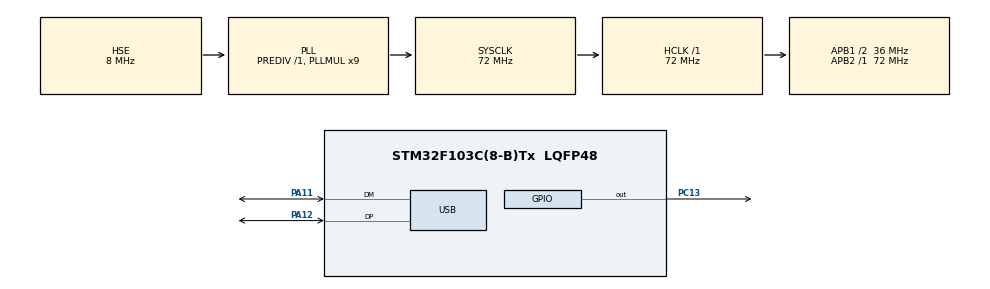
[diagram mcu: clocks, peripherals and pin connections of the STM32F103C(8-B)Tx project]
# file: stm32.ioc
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FREERTOS.Tasks01=defaultTask,24,128,StartDefaultTask,Default,NULL,Dynamic,NULL,NULL
FREERTOS.configTOTAL_HEAP_SIZE=1024*4
Mcu.Family=STM32F1
Mcu.Name=STM32F103C(8-B)Tx
Mcu.Package=LQFP48
NVIC.PriorityGroup=NVIC_PRIORITYGROUP_4
NVIC.TIM2_IRQn=true\:15\:0\:false\:false\:true\:false\:false\:true\:true
NVIC.TimeBase=TIM2_IRQn
NVIC.TimeBaseIP=TIM2
NVIC.USB_LP_CAN1_RX0_IRQn=true\:5\:0\:false\:false\:true\:true\:false\:true\:true
PA11.Mode=Device
PA11.Signal=USB_DM
PA12.Mode=Device
PA12.Signal=USB_DP
PA13.Mode=Serial_Wire
PA13.Signal=SYS_JTMS-SWDIO
PA14.Mode=Serial_Wire
PA14.Signal=SYS_JTCK-SWCLK
PC13-TAMPER-RTC.Signal=GPIO_Output
PD0-OSC_IN.Mode=HSE-External-Oscillator
PD0-OSC_IN.Signal=RCC_OSC_IN
PD1-OSC_OUT.Mode=HSE-External-Oscillator
PD1-OSC_OUT.Signal=RCC_OSC_OUT
ProjectManager.HeapSize=0x200
ProjectManager.StackSize=0x400
ProjectManager.TargetToolchain=CMake
RCC.AHBFreq_Value=72000000
RCC.APB1CLKDivider=RCC_HCLK_DIV2
RCC.APB1Freq_Value=36000000
RCC.APB1TimFreq_Value=72000000
RCC.APB2Freq_Value=72000000
RCC.APB2TimFreq_Value=72000000
RCC.HCLKFreq_Value=72000000
RCC.PLLMUL=RCC_PLL_MUL9
RCC.PLLSourceVirtual=RCC_PLLSOURCE_HSE
RCC.SYSCLKFreq_VALUE=72000000
RCC.SYSCLKSource=RCC_SYSCLKSOURCE_PLLCLK
RCC.USBFreq_Value=48000000
RCC.USBPrescaler=RCC_USBCLKSOURCE_PLL_DIV1_5
USB_DEVICE.CLASS_NAME_FS=CDC
USB_DEVICE.VirtualMode=Cdc
USB_DEVICE.VirtualModeFS=Cdc_FS
VP_FREERTOS_VS_CMSIS_V2.Mode=CMSIS_V2
VP_SYS_VS_tim2.Mode=TIM2
VP_USB_DEVICE_VS_USB_DEVICE_CDC_FS.Mode=CDC_FS
board=custom

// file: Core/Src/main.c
/* USER CODE BEGIN Header */
/**
 ******************************************************************************
 * @file           : main.c
 * @brief          : Main program body
 ******************************************************************************
 * @attention
 *
 * Copyright (c) 2025 STMicroelectronics.
 * All rights reserved.
 *
 * This software is licensed under terms that can be found in the LICENSE file
 * in the root directory of this software component.
 * If no LICENSE file comes with this software, it is provided AS-IS.
 *
 ******************************************************************************
 */
/* USER CODE END Header */
#include "main.h"
#include "cmsis_os.h"
#include "usb_device.h"

/* USER CODE BEGIN Includes */
#include "usbd_cdc_if.h"

#include "queue.h"
#include "stream_buffer.h"

#include "cs_usb_comms.h"
/* USER CODE END Includes */

/* USER CODE BEGIN PD */
#define CMD_BUFFER_MAX_LEN 32
#define CS_DEFAULT_PRIORITY (osPriorityNormal)

/* USER CODE END PD */

/* Definitions for defaultTask */
osThreadId_t defaultTaskHandle;
const osThreadAttr_t defaultTask_attributes = {
    .name = "defaultTask",
    .stack_size = 128 * 4,
    .priority = (osPriority_t)osPriorityNormal,
};
/* USER CODE BEGIN PV */
StreamBufferHandle_t sb_usb_recv_buffer;
QueueHandle_t q_usb_send_queue;

/* USER CODE END PV */

void SystemClock_Config(void);
static void MX_GPIO_Init(void);
void StartDefaultTask(void *argument);

/* USER CODE BEGIN PFP */
void usb_recv_ISR(uint8_t *buf, uint32_t len);

void task_usb_receiver(void *pargs);
void task_usb_sender(void *pargs);

/* USER CODE END PFP */

/* USER CODE BEGIN 0 */

void toggle_led()
{
    HAL_GPIO_TogglePin(GPIOC, GPIO_PIN_13);
}

/* USER CODE END 0 */

int main(void)
{

    /* MCU Configuration--------------------------------------------------------*/

    /* Reset of all peripherals, Initializes the Flash interface and the Systick. */
    HAL_Init();

    /* Configure the system clock */
    SystemClock_Config();

    /* Initialize all configured peripherals */
    MX_GPIO_Init();

    /* Init scheduler */
    osKernelInitialize();

    /* USER CODE BEGIN RTOS_QUEUES */
    q_usb_send_queue = xQueueCreate(2, sizeof(cs_response_msg));
    sb_usb_recv_buffer = xStreamBufferCreate(64, 1);
    /* USER CODE END RTOS_QUEUES */

    /* Create the thread(s) */
    /* creation of defaultTask */
    defaultTaskHandle = osThreadNew(StartDefaultTask, NULL, &defaultTask_attributes);

    /* USER CODE BEGIN RTOS_THREADS */
    BaseType_t created;
    created = xTaskCreate(task_usb_sender,
                          "senderTask",
                          configMINIMAL_STACK_SIZE,
                          NULL,
                          CS_DEFAULT_PRIORITY,
                          NULL);

    configASSERT(pdPASS == created);

    created = xTaskCreate(task_usb_receiver,
                          "recvTask",
                          configMINIMAL_STACK_SIZE * 3,
                          NULL,
                          CS_DEFAULT_PRIORITY,
                          NULL);

    configASSERT(pdPASS == created);
    /* USER CODE END RTOS_THREADS */

    /* Start scheduler */
    osKernelStart();

    /* We should never get here as control is now taken by the scheduler */

    /* Infinite loop */
    while (1)
    {

    }
}

void SystemClock_Config(void)
{
    RCC_OscInitTypeDef RCC_OscInitStruct = {0};
    RCC_ClkInitTypeDef RCC_ClkInitStruct = {0};
    RCC_PeriphCLKInitTypeDef PeriphClkInit = {0};

    /** Initializes the RCC Oscillators according to the specified parameters
     * in the RCC_OscInitTypeDef structure.
     */
    RCC_OscInitStruct.OscillatorType = RCC_OSCILLATORTYPE_HSE;
    RCC_OscInitStruct.HSEState = RCC_HSE_ON;
    RCC_OscInitStruct.HSEPredivValue = RCC_HSE_PREDIV_DIV1;
    RCC_OscInitStruct.HSIState = RCC_HSI_ON;
    RCC_OscInitStruct.PLL.PLLState = RCC_PLL_ON;
    RCC_OscInitStruct.PLL.PLLSource = RCC_PLLSOURCE_HSE;
    RCC_OscInitStruct.PLL.PLLMUL = RCC_PLL_MUL9;
    if (HAL_RCC_OscConfig(&RCC_OscInitStruct) != HAL_OK)
    {
        Error_Handler();
    }

    /** Initializes the CPU, AHB and APB buses clocks
     */
    RCC_ClkInitStruct.ClockType = RCC_CLOCKTYPE_HCLK | RCC_CLOCKTYPE_SYSCLK | RCC_CLOCKTYPE_PCLK1 | RCC_CLOCKTYPE_PCLK2;
    RCC_ClkInitStruct.SYSCLKSource = RCC_SYSCLKSOURCE_PLLCLK;
    RCC_ClkInitStruct.AHBCLKDivider = RCC_SYSCLK_DIV1;
    RCC_ClkInitStruct.APB1CLKDivider = RCC_HCLK_DIV2;
    RCC_ClkInitStruct.APB2CLKDivider = RCC_HCLK_DIV1;

    if (HAL_RCC_ClockConfig(&RCC_ClkInitStruct, FLASH_LATENCY_2) != HAL_OK)
    {
        Error_Handler();
    }
    PeriphClkInit.PeriphClockSelection = RCC_PERIPHCLK_USB;
    PeriphClkInit.UsbClockSelection = RCC_USBCLKSOURCE_PLL_DIV1_5;
    if (HAL_RCCEx_PeriphCLKConfig(&PeriphClkInit) != HAL_OK)
    {
        Error_Handler();
    }
}

static void MX_GPIO_Init(void)
{
    GPIO_InitTypeDef GPIO_InitStruct = {0};

    /* GPIO Ports Clock Enable */
    __HAL_RCC_GPIOC_CLK_ENABLE();
    __HAL_RCC_GPIOD_CLK_ENABLE();
    __HAL_RCC_GPIOA_CLK_ENABLE();

    /*Configure GPIO pin Output Level */
    HAL_GPIO_WritePin(GPIOC, GPIO_PIN_13, GPIO_PIN_RESET);

    /*Configure GPIO pin : PC13 */
    GPIO_InitStruct.Pin = GPIO_PIN_13;
    GPIO_InitStruct.Mode = GPIO_MODE_OUTPUT_PP;
    GPIO_InitStruct.Pull = GPIO_NOPULL;
    GPIO_InitStruct.Speed = GPIO_SPEED_FREQ_LOW;
    HAL_GPIO_Init(GPIOC, &GPIO_InitStruct);

}

/* USER CODE BEGIN 4 */
void usb_recv_ISR(uint8_t *buf, uint32_t len)
{
    BaseType_t xHigherPriorityTaskWoken = pdFALSE;

    xStreamBufferSendFromISR(sb_usb_recv_buffer, buf, len,
                             &xHigherPriorityTaskWoken);

    portYIELD_FROM_ISR(xHigherPriorityTaskWoken);
}

void task_usb_receiver(void *arg)
{
    for (;;)
    {
        size_t n = xStreamBufferReceive(sb_usb_recv_buffer,
                                        (void *)cs_get_remaining_cmd_buffer(),
                                        cs_get_remaining_cmd_buffer_len(),
                                        portMAX_DELAY);

        if (n == 0)
        {
            continue;
        }

        cs_updated_cmd_buffer(n);

        cs_command_id cmd;

        if (!cs_check_for_command(&cmd))
        {
            continue;
        }

        // cs_response_msg resp;

        switch (cmd)
        {
        case CMD_TOGGLE_LED:
            HAL_GPIO_TogglePin(GPIOC, GPIO_PIN_13);
            // resp.id = RESP_TEXT;
            // resp.payload = (cs_response_payload){
            //     .text = "OK"
            // };
            // cs_usb_send_blocking(&resp);
            break;
        case CMD_PING:
        {
            cs_response_msg resp = {.id = RESP_TEXT, .payload.text = "PONG"};
            xQueueSend(q_usb_send_queue, &resp, portMAX_DELAY);
            break;
        }
        case CMD_ERR:
        default:
        {
            cs_response_msg resp = {.id = RESP_ERR, .payload.text = "unknown cmd"};
            xQueueSend(q_usb_send_queue, &resp, portMAX_DELAY);
            break;
        }
        }
    }
}

void task_usb_sender(void *arg)
{
    for (;;)
    {
        cs_response_msg resp = {0};

        if (pdPASS != xQueueReceive(q_usb_send_queue, &resp, portMAX_DELAY))
        {
            continue;
        }

        switch (resp.id)
        {
        default:
            // use text buffer by default
            size_t len = strnlen(resp.payload.text, sizeof(resp.payload.text));
            CDC_Transmit_FS((uint8_t *)resp.payload.text, len);
            break;
        }
    }
}

// FreeRTOS hooks/assert hanndler
void vApplicationMallocFailedHook(void)
{
    taskDISABLE_INTERRUPTS();
    for (;;)
        ;
}

void vApplicationStackOverflowHook(TaskHandle_t xTask, char *pcTaskName)
{
    (void)xTask;
    (void)pcTaskName;
    taskDISABLE_INTERRUPTS();
    for (;;)
        ;
}

void vAssertCalled(const char *file, int line)
{
    (void)file;
    (void)line;

    taskDISABLE_INTERRUPTS();
    __BKPT(0); // breakpoint. Lets gdb inspect file and line
    for (;;)
    {
    }
}
/* USER CODE END 4 */

void StartDefaultTask(void *argument)
{
    /* init code for USB_DEVICE */
    MX_USB_DEVICE_Init();
    /* USER CODE BEGIN 5 */
    // UBaseType_t shwm;
    /* Infinite loop */
    for (;;)
    {
        osDelay(pdMS_TO_TICKS(1000));
        // shwm = uxTaskGetStackHighWaterMark(NULL);
        // (void) shwm;
    }
    /* USER CODE END 5 */
}

void HAL_TIM_PeriodElapsedCallback(TIM_HandleTypeDef *htim)
{
    if (htim->Instance == TIM2)
    {
        HAL_IncTick();
    }
}

void Error_Handler(void)
{
    __disable_irq();
    while (1)
    {
    }
}
